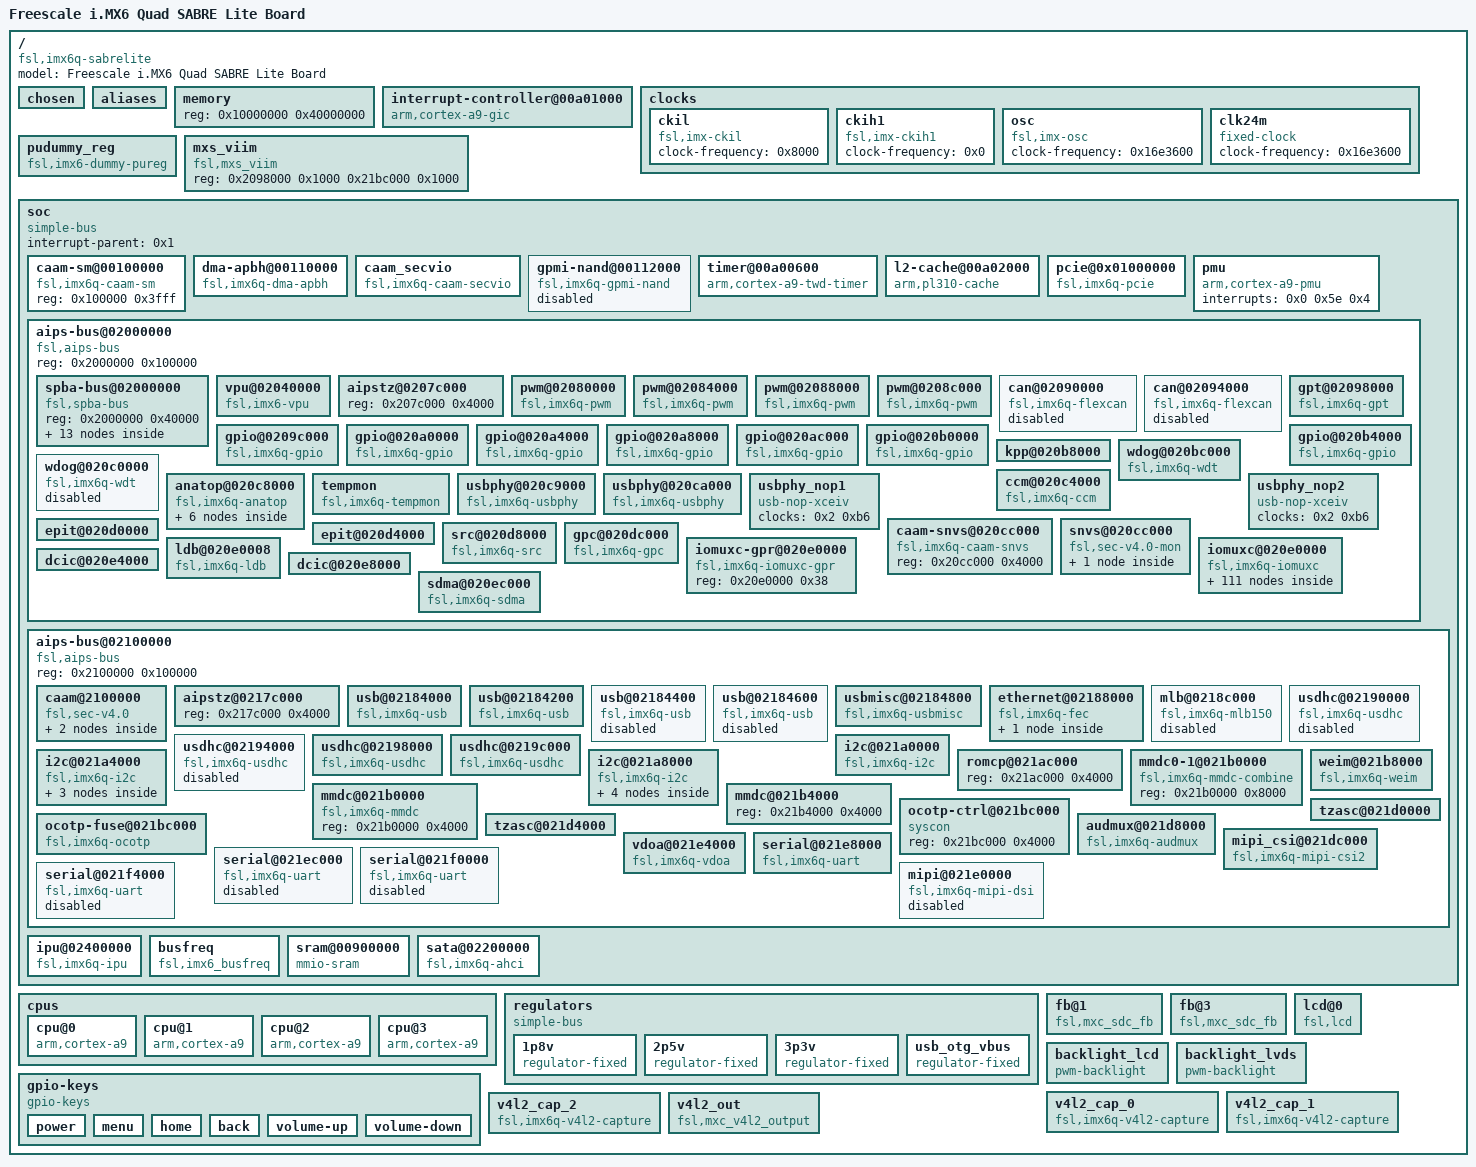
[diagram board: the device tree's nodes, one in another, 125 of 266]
/dts-v1/;

/ {
	#address-cells = <0x1>;
	#size-cells = <0x1>;
	model = "Freescale i.MX6 Quad SABRE Lite Board";
	compatible = "fsl,imx6q-sabrelite", "fsl,imx6q";

	chosen {
	//	bootargs = "console=ttymxc1,115200 root=/dev/mmcblk1p2 rw rootwait earlyprintk initcall_debug=1 loglevel=8 mem=862M no_console_suspend video=mxcfb0:dev=ldb,LDB-XGA,if=RGB888";
	bootargs = "console=ttymxc1,115200 root=/dev/mmcblk0 rw rootwait earlyprintk initcall_debug=1 loglevel=8 mem=862M no_console_suspend video=mxcfb1:dev=ldb,LDB-XGA,if=RGB666 ip=dhcp";
	};

	aliases {
		flexcan0 = "/soc/aips-bus@02000000/can@02090000";
		flexcan1 = "/soc/aips-bus@02000000/can@02094000";
		gpio0 = "/soc/aips-bus@02000000/gpio@0209c000";
		gpio1 = "/soc/aips-bus@02000000/gpio@020a0000";
		gpio2 = "/soc/aips-bus@02000000/gpio@020a4000";
		gpio3 = "/soc/aips-bus@02000000/gpio@020a8000";
		gpio4 = "/soc/aips-bus@02000000/gpio@020ac000";
		gpio5 = "/soc/aips-bus@02000000/gpio@020b0000";
		gpio6 = "/soc/aips-bus@02000000/gpio@020b4000";
		ipu0 = "/soc/ipu@02400000";
		serial0 = "/soc/aips-bus@02000000/spba-bus@02000000/serial@02020000";
		serial1 = "/soc/aips-bus@02100000/serial@021e8000";
		serial2 = "/soc/aips-bus@02100000/serial@021ec000";
		serial3 = "/soc/aips-bus@02100000/serial@021f0000";
		serial4 = "/soc/aips-bus@02100000/serial@021f4000";
		usbphy0 = "/soc/aips-bus@02000000/usbphy@020c9000";
		usbphy1 = "/soc/aips-bus@02000000/usbphy@020ca000";
		mxcfb0 = "/fb@0";
		mxcfb1 = "/fb@1";
		mxcfb2 = "/fb@2";
		mxcfb3 = "/fb@3";
	};

	memory {
		device_type = "memory";
		reg = <0x10000000 0x40000000>;
	};

	interrupt-controller@00a01000 {
		compatible = "arm,cortex-a9-gic";
		#interrupt-cells = <0x3>;
		#address-cells = <0x1>;
		#size-cells = <0x1>;
		interrupt-controller;
		reg = <0xa01000 0x1000 0xa00100 0x100>;
		linux,phandle = <0x1>;
		phandle = <0x1>;
	};

	clocks {
		#address-cells = <0x1>;
		#size-cells = <0x0>;

		ckil {
			compatible = "fsl,imx-ckil", "fixed-clock";
			clock-frequency = <0x8000>;
		};

		ckih1 {
			compatible = "fsl,imx-ckih1", "fixed-clock";
			clock-frequency = <0x0>;
		};

		osc {
			compatible = "fsl,imx-osc", "fixed-clock";
			clock-frequency = <0x16e3600>;
		};

		clk24m {
			compatible = "fixed-clock";
			#clock-cells = <0x0>;
			clock-frequency = <0x16e3600>;
			linux,phandle = <0x2a>;
			phandle = <0x2a>;
		};
		
	};

	pudummy_reg {
		compatible = "fsl,imx6-dummy-pureg";
	};

	mxs_viim {
		compatible = "fsl,mxs_viim";
		reg = <0x2098000 0x1000 0x21bc000 0x1000>;
	};

	soc {
		#address-cells = <0x1>;
		#size-cells = <0x1>;
		compatible = "simple-bus";
		interrupt-parent = <0x1>;
		ranges;

		caam-sm@00100000 {
			compatible = "fsl,imx6q-caam-sm";
			reg = <0x100000 0x3fff>;
		};

		dma-apbh@00110000 {
			compatible = "fsl,imx6q-dma-apbh", "fsl,imx28-dma-apbh";
			reg = <0x110000 0x2000>;
			interrupts = <0x0 0xd 0x4 0x0 0xd 0x4 0x0 0xd 0x4 0x0 0xd 0x4>;
			interrupt-names = "gpmi0", "gpmi1", "gpmi2", "gpmi3";
			#dma-cells = <0x1>;
			dma-channels = <0x4>;
			clocks = <0x2 0x6a>;
			linux,phandle = <0x3>;
			phandle = <0x3>;
		};

		caam_secvio {
			compatible = "fsl,imx6q-caam-secvio";
			interrupts = <0x0 0x14 0x4>;
			secvio_src = <0x8000001d>;
		};

		gpmi-nand@00112000 {
			compatible = "fsl,imx6q-gpmi-nand";
			#address-cells = <0x1>;
			#size-cells = <0x1>;
			reg = <0x112000 0x2000 0x114000 0x2000>;
			reg-names = "gpmi-nand", "bch";
			interrupts = <0x0 0xf 0x4>;
			interrupt-names = "bch";
			clocks = <0x2 0x98 0x2 0x99 0x2 0x97 0x2 0x96 0x2 0x95>;
			clock-names = "gpmi_io", "gpmi_apb", "gpmi_bch", "gpmi_bch_apb", "per1_bch";
			dmas = <0x3 0x0>;
			dma-names = "rx-tx";
			status = "disabled";
		};

		timer@00a00600 {
			compatible = "arm,cortex-a9-twd-timer";
			reg = <0xa00600 0x20>;
			interrupts = <0x1 0xd 0xf01>;
			clocks = <0x2 0xf>;
		};

		l2-cache@00a02000 {
			compatible = "arm,pl310-cache";
			reg = <0xa02000 0x1000>;
			interrupts = <0x0 0x5c 0x4>;
			cache-unified;
			cache-level = <0x2>;
			arm,tag-latency = <0x4 0x2 0x3>;
			arm,data-latency = <0x4 0x2 0x3>;
			linux,phandle = <0x2e>;
			phandle = <0x2e>;
		};

		pcie@0x01000000 {
			compatible = "fsl,imx6q-pcie", "snps,dw-pcie";
			reg = <0x1ffc000 0x4000>;
			#address-cells = <0x3>;
			#size-cells = <0x2>;
			device_type = "pci";
			ranges = <0x800 0x0 0x1f00000 0x1f00000 0x0 0x80000 0x81000000 0x0 0x0 0x1f80000 0x0 0x10000 0x82000000 0x0 0x1000000 0x1000000 0x0 0xf00000>;
			num-lanes = <0x1>;
			interrupts = <0x0 0x7b 0x4>;
			clocks = <0x2 0xbd 0x2 0xbb 0x2 0x90 0x2 0xd4>;
			clock-names = "pcie_ref_125m", "sata_ref_100m", "pcie_axi", "lvds_gate";
			status = "okay";
		};

		pmu {
			compatible = "arm,cortex-a9-pmu";
			interrupts = <0x0 0x5e 0x4>;
		};

		aips-bus@02000000 {
			compatible = "fsl,aips-bus", "simple-bus";
			#address-cells = <0x1>;
			#size-cells = <0x1>;
			reg = <0x2000000 0x100000>;
			ranges;

			spba-bus@02000000 {
				compatible = "fsl,spba-bus", "simple-bus";
				#address-cells = <0x1>;
				#size-cells = <0x1>;
				reg = <0x2000000 0x40000>;
				ranges;

				spdif@02004000 {
					compatible = "fsl,imx6q-spdif", "fsl,imx35-spdif";
					reg = <0x2004000 0x4000>;
					interrupts = <0x0 0x34 0x4>;
					dmas = <0x4 0xe 0x12 0x0 0x4 0xf 0x12 0x0>;
					dma-names = "rx", "tx";
					clocks = <0x2 0xc5 0x2 0x3 0x2 0xc5 0x2 0x6b 0x2 0x0 0x2 0x76 0x2 0x3e 0x2 0x8b 0x2 0x0 0x2 0x9c>;
					clock-names = "core", "rxtx0", "rxtx1", "rxtx2", "rxtx3", "rxtx4", "rxtx5", "rxtx6", "rxtx7", "dma";
					status = "disabled";
				};

/*
				ecspi@02008000 {
					#address-cells = <0x1>;
					#size-cells = <0x0>;
					compatible = "fsl,imx6q-ecspi", "fsl,imx51-ecspi";
					reg = <0x2008000 0x4000>;
					interrupts = <0x0 0x1f 0x4>;
					clocks = <0x2 0x70 0x2 0x70>;
					clock-names = "ipg", "per";
					status = "okay";
					fsl,spi-num-chipselects = <0x1>;
					cs-gpios = <0x5 0x13 0x0>;
					pinctrl-names = "default";
					pinctrl-0 = <0x6>;

					m25p80@0 {
						compatible = "sst,sst25vf016b";
						spi-max-frequency = <0x1312d00>;
						reg = <0x0>;
						#address-cells = <0x1>;
						#size-cells = <0x1>;

						partition@0 {
							label = "U-Boot";
							reg = <0x0 0xc0000>;
							read-only;
						};

						partition@C0000 {
							label = "env";
							reg = <0xc0000 0x2000>;
							read-only;
						};

						partition@C2000 {
							label = "Kernel";
							reg = <0xc2000 0x13e000>;
						};
					};
				};
*/
				ecspi@0200c000 {
					#address-cells = <0x1>;
					#size-cells = <0x0>;
					compatible = "fsl,imx6q-ecspi", "fsl,imx51-ecspi";
					reg = <0x200c000 0x4000>;
					interrupts = <0x0 0x20 0x4>;
					clocks = <0x2 0x71 0x2 0x71>;
					clock-names = "ipg", "per";
					status = "disabled";
				};

				ecspi@02010000 {
					#address-cells = <0x1>;
					#size-cells = <0x0>;
					compatible = "fsl,imx6q-ecspi", "fsl,imx51-ecspi";
					reg = <0x2010000 0x4000>;
					interrupts = <0x0 0x21 0x4>;
					clocks = <0x2 0x72 0x2 0x72>;
					clock-names = "ipg", "per";
					status = "disabled";
				};

				ecspi@02014000 {
					#address-cells = <0x1>;
					#size-cells = <0x0>;
					compatible = "fsl,imx6q-ecspi", "fsl,imx51-ecspi";
					reg = <0x2014000 0x4000>;
					interrupts = <0x0 0x22 0x4>;
					clocks = <0x2 0x73 0x2 0x73>;
					clock-names = "ipg", "per";
					status = "disabled";
				};

				serial@02020000 {
					compatible = "fsl,imx6q-uart", "fsl,imx21-uart";
					reg = <0x2020000 0x4000>;
					interrupts = <0x0 0x1a 0x4>;
					clocks = <0x2 0xa0 0x2 0xa1>;
					clock-names = "ipg", "per";
					dmas = <0x4 0x19 0x4 0x0 0x4 0x1a 0x4 0x0>;
					dma-names = "rx", "tx";
					status = "okay";
					pinctrl-names = "default";
					pinctrl-0 = <0x7>;
				};

				esai@02024000 {
					compatible = "fsl,imx6q-esai";
					reg = <0x2024000 0x4000>;
					interrupts = <0x0 0x33 0x4>;
					clocks = <0x2 0x76 0x2 0x9c>;
					clock-names = "core", "dma";
					fsl,esai-dma-events = <0x18 0x17>;
					fsl,flags = <0x1>;
					status = "disabled";
				};

				ssi@02028000 {
					compatible = "fsl,imx6q-ssi", "fsl,imx21-ssi";
					reg = <0x2028000 0x4000>;
					interrupts = <0x0 0x2e 0x4>;
					clocks = <0x2 0xb2 0x2 0x9d>;
					clock-names = "ipg", "baud";
					dmas = <0x4 0x25 0x1 0x0 0x4 0x26 0x1 0x0>;
					dma-names = "rx", "tx";
					status = "okay";
					fsl,mode = "i2s-slave";
					linux,phandle = <0x31>;
					phandle = <0x31>;
				};

				ssi@0202c000 {
					compatible = "fsl,imx6q-ssi", "fsl,imx21-ssi";
					reg = <0x202c000 0x4000>;
					interrupts = <0x0 0x2f 0x4>;
					clocks = <0x2 0xb3 0x2 0x9e>;
					clock-names = "ipg", "baud";
					dmas = <0x4 0x29 0x1 0x0 0x4 0x2a 0x1 0x0>;
					dma-names = "rx", "tx";
					status = "disabled";
				};

				ssi@02030000 {
					compatible = "fsl,imx6q-ssi", "fsl,imx21-ssi";
					reg = <0x2030000 0x4000>;
					interrupts = <0x0 0x30 0x4>;
					clocks = <0x2 0xb4 0x2 0x9f>;
					clock-names = "ipg", "baud";
					dmas = <0x4 0x2d 0x1 0x0 0x4 0x2e 0x1 0x0>;
					dma-names = "rx", "tx";
					status = "disabled";
				};

				asrc@02034000 {
					compatible = "fsl,imx53-asrc";
					reg = <0x2034000 0x4000>;
					interrupts = <0x0 0x32 0x4>;
					clocks = <0x2 0x6b 0x2 0x9c>;
					clock-names = "core", "dma";
					dmas = <0x4 0x11 0x14 0x1 0x4 0x12 0x14 0x1 0x4 0x13 0x14 0x1 0x4 0x14 0x14 0x1 0x4 0x15 0x14 0x1 0x4 0x16 0x14 0x1>;
					dma-names = "rxa", "rxb", "rxc", "txa", "txb", "txc";
					status = "okay";
				};

				asrc_p2p {
					compatible = "fsl,imx6q-asrc-p2p";
					fsl,output-rate = <0xbb80>;
					fsl,output-width = <0x10>;
					fsl,asrc-dma-rx-events = <0x11 0x12 0x13>;
					fsl,asrc-dma-tx-events = <0x14 0x15 0x16>;
					status = "okay";
				};

				spba@0203c000 {
					reg = <0x203c000 0x4000>;
				};

				ecspi@02018000 {
					#address-cells = <0x1>;
					#size-cells = <0x0>;
					compatible = "fsl,imx6q-ecspi", "fsl,imx51-ecspi";
					reg = <0x2018000 0x4000>;
					interrupts = <0x0 0x23 0x4>;
					clocks = <0x2 0x74 0x2 0x74>;
					clock-names = "ipg", "per";
					status = "disabled";
				};
			};

			vpu@02040000 {
				compatible = "fsl,imx6-vpu";
				reg = <0x2040000 0x3c000>;
				reg-names = "vpu_regs";
				interrupts = <0x0 0x3 0x1 0x0 0xc 0x4>;
				interrupt-names = "vpu_jpu_irq", "vpu_ipi_irq";
				clocks = <0x2 0xa8 0x2 0x8c 0x2 0x8e>;
				clock-names = "vpu_clk", "mmdc_ch0_axi", "ocram";
				iramsize = <0x21000>;
				iram = <0x8>;
				resets = <0x9 0x1>;
				pu-supply = <0xa>;
				status = "okay";
			};

			aipstz@0207c000 {
				reg = <0x207c000 0x4000>;
			};

			pwm@02080000 {
				#pwm-cells = <0x2>;
				compatible = "fsl,imx6q-pwm", "fsl,imx27-pwm";
				reg = <0x2080000 0x4000>;
				interrupts = <0x0 0x53 0x4>;
				clocks = <0x2 0x3e 0x2 0x91>;
				clock-names = "ipg", "per";
				pinctrl-names = "default";
				pinctrl-0 = <0xb>;
				status = "okay";
				linux,phandle = <0x34>;
				phandle = <0x34>;
			};

			pwm@02084000 {
				#pwm-cells = <0x2>;
				compatible = "fsl,imx6q-pwm", "fsl,imx27-pwm";
				reg = <0x2084000 0x4000>;
				interrupts = <0x0 0x54 0x4>;
				clocks = <0x2 0x3e 0x2 0x92>;
				clock-names = "ipg", "per";
			};

			pwm@02088000 {
				#pwm-cells = <0x2>;
				compatible = "fsl,imx6q-pwm", "fsl,imx27-pwm";
				reg = <0x2088000 0x4000>;
				interrupts = <0x0 0x55 0x4>;
				clocks = <0x2 0x3e 0x2 0x93>;
				clock-names = "ipg", "per";
				pinctrl-names = "default";
				pinctrl-0 = <0xc>;
				status = "okay";
				linux,phandle = <0x26>;
				phandle = <0x26>;
			};

			pwm@0208c000 {
				#pwm-cells = <0x2>;
				compatible = "fsl,imx6q-pwm", "fsl,imx27-pwm";
				reg = <0x208c000 0x4000>;
				interrupts = <0x0 0x56 0x4>;
				clocks = <0x2 0x3e 0x2 0x94>;
				clock-names = "ipg", "per";
				pinctrl-names = "default";
				pinctrl-0 = <0xd>;
				status = "okay";
				linux,phandle = <0x35>;
				phandle = <0x35>;
			};

			can@02090000 {
				compatible = "fsl,imx6q-flexcan";
				reg = <0x2090000 0x4000>;
				interrupts = <0x0 0x6e 0x4>;
				clocks = <0x2 0x6c 0x2 0x6d>;
				clock-names = "ipg", "per";
				gpr = <0xe>;
				status = "disabled";
			};

			can@02094000 {
				compatible = "fsl,imx6q-flexcan";
				reg = <0x2094000 0x4000>;
				interrupts = <0x0 0x6f 0x4>;
				clocks = <0x2 0x6e 0x2 0x6f>;
				clock-names = "ipg", "per";
				gpr = <0xe>;
				status = "disabled";
			};

			gpt@02098000 {
				compatible = "fsl,imx6q-gpt";
				reg = <0x2098000 0x4000>;
				interrupts = <0x0 0x37 0x4>;
				clocks = <0x2 0x77 0x2 0x78>;
				clock-names = "ipg", "per";
				status = "okay";
			};

			gpio@0209c000 {
				compatible = "fsl,imx6q-gpio", "fsl,imx35-gpio";
				reg = <0x209c000 0x4000>;
				interrupts = <0x0 0x42 0x4 0x0 0x43 0x4>;
				gpio-controller;
				#gpio-cells = <0x2>;
				interrupt-controller;
				#interrupt-cells = <0x2>;
				linux,phandle = <0x1a>;
				phandle = <0x1a>;
			};

			gpio@020a0000 {
				compatible = "fsl,imx6q-gpio", "fsl,imx35-gpio";
				reg = <0x20a0000 0x4000>;
				interrupts = <0x0 0x44 0x4 0x0 0x45 0x4>;
				gpio-controller;
				#gpio-cells = <0x2>;
				interrupt-controller;
				#interrupt-cells = <0x2>;
				linux,phandle = <0x1f>;
				phandle = <0x1f>;
			};

			gpio@020a4000 {
				compatible = "fsl,imx6q-gpio", "fsl,imx35-gpio";
				reg = <0x20a4000 0x4000>;
				interrupts = <0x0 0x46 0x4 0x0 0x47 0x4>;
				gpio-controller;
				#gpio-cells = <0x2>;
				interrupt-controller;
				#interrupt-cells = <0x2>;
				linux,phandle = <0x5>;
				phandle = <0x5>;
			};

			gpio@020a8000 {
				compatible = "fsl,imx6q-gpio", "fsl,imx35-gpio";
				reg = <0x20a8000 0x4000>;
				interrupts = <0x0 0x48 0x4 0x0 0x49 0x4>;
				gpio-controller;
				#gpio-cells = <0x2>;
				interrupt-controller;
				#interrupt-cells = <0x2>;
				linux,phandle = <0x2b>;
				phandle = <0x2b>;
			};

			gpio@020ac000 {
				compatible = "fsl,imx6q-gpio", "fsl,imx35-gpio";
				reg = <0x20ac000 0x4000>;
				interrupts = <0x0 0x4a 0x4 0x0 0x4b 0x4>;
				gpio-controller;
				#gpio-cells = <0x2>;
				interrupt-controller;
				#interrupt-cells = <0x2>;
			};

			gpio@020b0000 {
				compatible = "fsl,imx6q-gpio", "fsl,imx35-gpio";
				reg = <0x20b0000 0x4000>;
				interrupts = <0x0 0x4c 0x4 0x0 0x4d 0x4>;
				gpio-controller;
				#gpio-cells = <0x2>;
				interrupt-controller;
				#interrupt-cells = <0x2>;
				linux,phandle = <0x25>;
				phandle = <0x25>;
			};

			gpio@020b4000 {
				compatible = "fsl,imx6q-gpio", "fsl,imx35-gpio";
				reg = <0x20b4000 0x4000>;
				interrupts = <0x0 0x4e 0x4 0x0 0x4f 0x4>;
				gpio-controller;
				#gpio-cells = <0x2>;
				interrupt-controller;
				#interrupt-cells = <0x2>;
				linux,phandle = <0x1c>;
				phandle = <0x1c>;
			};

			kpp@020b8000 {
				reg = <0x20b8000 0x4000>;
				interrupts = <0x0 0x52 0x4>;
			};

			wdog@020bc000 {
				compatible = "fsl,imx6q-wdt", "fsl,imx21-wdt";
				reg = <0x20bc000 0x4000>;
				interrupts = <0x0 0x50 0x4>;
				clocks = <0x2 0x0>;
			};

			wdog@020c0000 {
				compatible = "fsl,imx6q-wdt", "fsl,imx21-wdt";
				reg = <0x20c0000 0x4000>;
				interrupts = <0x0 0x51 0x4>;
				clocks = <0x2 0x0>;
				status = "disabled";
			};

			ccm@020c4000 {
				compatible = "fsl,imx6q-ccm";
				reg = <0x20c4000 0x4000>;
				interrupts = <0x0 0x57 0x4 0x0 0x58 0x4>;
				#clock-cells = <0x1>;
				linux,phandle = <0x2>;
				phandle = <0x2>;
			};

			anatop@020c8000 {
				compatible = "fsl,imx6q-anatop", "syscon", "simple-bus";
				reg = <0x20c8000 0x1000>;
				interrupts = <0x0 0x31 0x4 0x0 0x36 0x4 0x0 0x7f 0x4>;
				linux,phandle = <0xf>;
				phandle = <0xf>;

				regulator-1p1@110 {
					compatible = "fsl,anatop-regulator";
					regulator-name = "vdd1p1";
					regulator-min-microvolt = <0xc3500>;
					regulator-max-microvolt = <0x14fb18>;
					regulator-always-on;
					anatop-reg-offset = <0x110>;
					anatop-vol-bit-shift = <0x8>;
					anatop-vol-bit-width = <0x5>;
					anatop-min-bit-val = <0x4>;
					anatop-min-voltage = <0xc3500>;
					anatop-max-voltage = <0x14fb18>;
				};

				regulator-3p0@120 {
					compatible = "fsl,anatop-regulator";
					regulator-name = "vdd3p0";
					regulator-min-microvolt = <0x2ab980>;
					regulator-max-microvolt = <0x3010b0>;
					regulator-always-on;
					anatop-reg-offset = <0x120>;
					anatop-vol-bit-shift = <0x8>;
					anatop-vol-bit-width = <0x5>;
					anatop-min-bit-val = <0x0>;
					anatop-min-voltage = <0x280de8>;
					anatop-max-voltage = <0x33e140>;
				};

				regulator-2p5@130 {
					compatible = "fsl,anatop-regulator";
					regulator-name = "vdd2p5";
					regulator-min-microvolt = <0x1e8480>;
					regulator-max-microvolt = <0x29f630>;
					regulator-always-on;
					anatop-reg-offset = <0x130>;
					anatop-vol-bit-shift = <0x8>;
					anatop-vol-bit-width = <0x5>;
					anatop-min-bit-val = <0x0>;
					anatop-min-voltage = <0x1e8480>;
					anatop-max-voltage = <0x29f630>;
				};

				regulator-vddcore@140 {
					compatible = "fsl,anatop-regulator";
					regulator-name = "cpu";
					regulator-min-microvolt = <0xb1008>;
					regulator-max-microvolt = <0x162010>;
					regulator-always-on;
					anatop-reg-offset = <0x140>;
					anatop-vol-bit-shift = <0x0>;
					anatop-vol-bit-width = <0x5>;
					anatop-delay-reg-offset = <0x170>;
					anatop-delay-bit-shift = <0x18>;
					anatop-delay-bit-width = <0x2>;
					anatop-min-bit-val = <0x1>;
					anatop-min-voltage = <0xb1008>;
					anatop-max-voltage = <0x162010>;
					linux,phandle = <0x2f>;
					phandle = <0x2f>;
				};

				regulator-vddpu@140 {
					compatible = "fsl,anatop-regulator";
					regulator-name = "vddpu";
					regulator-min-microvolt = <0xb1008>;
					regulator-max-microvolt = <0x162010>;
					anatop-reg-offset = <0x140>;
					anatop-vol-bit-shift = <0x9>;
					anatop-vol-bit-width = <0x5>;
					anatop-delay-reg-offset = <0x170>;
					anatop-delay-bit-shift = <0x1a>;
					anatop-delay-bit-width = <0x2>;
					anatop-min-bit-val = <0x1>;
					anatop-min-voltage = <0xb1008>;
					anatop-max-voltage = <0x162010>;
					linux,phandle = <0xa>;
					phandle = <0xa>;
				};

				regulator-vddsoc@140 {
					compatible = "fsl,anatop-regulator";
					regulator-name = "vddsoc";
					regulator-min-microvolt = <0xb1008>;
					regulator-max-microvolt = <0x162010>;
					regulator-always-on;
					anatop-reg-offset = <0x140>;
					anatop-vol-bit-shift = <0x12>;
					anatop-vol-bit-width = <0x5>;
					anatop-delay-reg-offset = <0x170>;
					anatop-delay-bit-shift = <0x1c>;
					anatop-delay-bit-width = <0x2>;
					anatop-min-bit-val = <0x1>;
					anatop-min-voltage = <0xb1008>;
					anatop-max-voltage = <0x162010>;
					linux,phandle = <0x30>;
					phandle = <0x30>;
				};
			};

			tempmon {
				compatible = "fsl,imx6q-tempmon";
				interrupts = <0x0 0x31 0x4>;
				fsl,tempmon = <0xf>;
				fsl,tempmon-data = <0x10>;
				clocks = <0x2 0xac>;
			};

			usbphy@020c9000 {
				compatible = "fsl,imx6q-usbphy", "fsl,imx23-usbphy";
				reg = <0x20c9000 0x1000>;
				interrupts = <0x0 0x2c 0x4>;
				clocks = <0x2 0xb6>;
				fsl,anatop = <0xf>;
				linux,phandle = <0x12>;
				phandle = <0x12>;
			};

			usbphy@020ca000 {
				compatible = "fsl,imx6q-usbphy", "fsl,imx23-usbphy";
				reg = <0x20ca000 0x1000>;
				interrupts = <0x0 0x2d 0x4>;
				clocks = <0x2 0xb7>;
				fsl,anatop = <0xf>;
				linux,phandle = <0x16>;
				phandle = <0x16>;
			};

			usbphy_nop1 {
				compatible = "usb-nop-xceiv";
				clocks = <0x2 0xb6>;
				clock-names = "main_clk";
				linux,phandle = <0x17>;
				phandle = <0x17>;
			};

			usbphy_nop2 {
				compatible = "usb-nop-xceiv";
				clocks = <0x2 0xb6>;
				clock-names = "main_clk";
				linux,phandle = <0x18>;
				phandle = <0x18>;
			};

			caam-snvs@020cc000 {
				compatible = "fsl,imx6q-caam-snvs";
				reg = <0x20cc000 0x4000>;
			};

			snvs@020cc000 {
				compatible = "fsl,sec-v4.0-mon", "simple-bus";
				#address-cells = <0x1>;
				#size-cells = <0x1>;
				ranges = <0x0 0x20cc000 0x4000>;

				snvs-rtc-lp@34 {
					compatible = "fsl,sec-v4.0-mon-rtc-lp";
					reg = <0x34 0x58>;
					interrupts = <0x0 0x13 0x4 0x0 0x14 0x4>;
				};
			};

			epit@020d0000 {
				reg = <0x20d0000 0x4000>;
				interrupts = <0x0 0x38 0x4>;
			};

			epit@020d4000 {
				reg = <0x20d4000 0x4000>;
				interrupts = <0x0 0x39 0x4>;
			};

			src@020d8000 {
				compatible = "fsl,imx6q-src", "fsl,imx51-src";
				reg = <0x20d8000 0x4000>;
				interrupts = <0x0 0x5b 0x4 0x0 0x60 0x4>;
				#reset-cells = <0x1>;
				linux,phandle = <0x9>;
				phandle = <0x9>;
			};

			gpc@020dc000 {
				compatible = "fsl,imx6q-gpc";
				reg = <0x20dc000 0x4000>;
				interrupts = <0x0 0x59 0x4 0x0 0x5a 0x4>;
				clocks = <0x2 0x7a 0x2 0x4a 0x2 0x79 0x2 0x1a 0x2 0x8f 0x2 0xa8 0x2 0x3e>;
				clock-names = "gpu3d_core", "gpu3d_shader", "gpu2d_core", "gpu2d_axi", "openvg_axi", "vpu_axi", "ipg";
				pu-supply = <0xa>;
			};

			iomuxc-gpr@020e0000 {
				compatible = "fsl,imx6q-iomuxc-gpr", "syscon";
				reg = <0x20e0000 0x38>;
				linux,phandle = <0xe>;
				phandle = <0xe>;
			};

			iomuxc@020e0000 {
				reg = <0x20e0000 0x4000>;
				compatible = "fsl,imx6q-iomuxc";
				pinctrl-names = "default";
				pinctrl-0 = <0x11>;

				audmux {

					audmux-1 {
						fsl,pins = <0x54 0x368 0x7b4 0x3 0x0 0x130b0 0x35c 0x744 0x7c4 0x3 0x1 0x130b0 0x50 0x364 0x7b8 0x3 0x0 0x110b0 0x4c 0x360 0x7c8 0x3 0x0 0x130b0>;
						linux,phandle = <0x2c>;
						phandle = <0x2c>;
					};

					audmux-2 {
						fsl,pins = <0x274 0x644 0x0 0x4 0x0 0x130b0 0x268 0x638 0x0 0x4 0x0 0x130b0 0x26c 0x63c 0x0 0x4 0x0 0x110b0 0x270 0x640 0x0 0x4 0x0 0x130b0>;
					};

					audmux-3 {
						fsl,pins = <0x1b0 0x4c4 0x7dc 0x3 0x0 0x130b0 0x1b8 0x4cc 0x7e0 0x3 0x0 0x130b0 0x1bc 0x4d0 0x7cc 0x3 0x0 0x130b0>;
					};
				};

				ecspi1 {

					ecspi1_cs_grp-1 {
						fsl,pins = <0x9c 0x3b0 0x0 0x5 0x0 0x80000000>;
					};

					ecspi1grp-1 {
						fsl,pins = <0x94 0x3a8 0x7f8 0x1 0x0 0x100b1 0x98 0x3ac 0x7fc 0x1 0x0 0x100b1 0x90 0x3a4 0x7f4 0x1 0x0 0x100b1>;
						linux,phandle = <0x6>;
						phandle = <0x6>;
					};

					ecspi1grp-2 {
						fsl,pins = <0x200 0x5d0 0x7f8 0x0 0x2 0x100b1 0x1fc 0x5cc 0x7fc 0x0 0x2 0x100b1 0x1f8 0x5c8 0x7f4 0x0 0x2 0x100b1>;
					};
				};

				ecspi3 {

					ecspi3grp-1 {
						fsl,pins = <0x178 0x48c 0x0 0x2 0x0 0x100b1 0x174 0x488 0x0 0x2 0x0 0x100b1 0x170 0x484 0x0 0x2 0x0 0x100b1>;
					};
				};

				enet {

					enetgrp-1 {
						fsl,pins = <0x1d0 0x4e4 0x840 0x1 0x0 0x1b0b0 0x1f4 0x508 0x0 0x1 0x0 0x1b0b0 0x58 0x36c 0x0 0x1 0x0 0x1b0b0 0x5c 0x370 0x0 0x1 0x0 0x1b0b0 0x60 0x374 0x0 0x1 0x0 0x1b0b0 0x64 0x378 0x0 0x1 0x0 0x1b0b0 0x68 0x37c 0x0 0x1 0x0 0x1b0b0 0x74 0x388 0x0 0x1 0x0 0x1b0b0 0x1d4 0x4e8 0x0 0x1 0x0 0x1b0b0 0x84 0x398 0x844 0x1 0x0 0x1b0b0 0x70 0x384 0x848 0x1 0x0 0x1b0b0 0x78 0x38c 0x84c 0x1 0x0 0x1b0b0 0x7c 0x390 0x850 0x1 0x0 0x1b0b0 0x80 0x394 0x854 0x1 0x0 0x1b0b0 0x6c 0x380 0x858 0x1 0x0 0x1b0b0 0x248 0x618 0x83c 0x2 0x1 0x4001b0a8>;
					};

					enetgrp-2 {
						fsl,pins = <0x200 0x5d0 0x840 0x1 0x1 0x1b0b0 0x208 0x5d8 0x0 0x4 0x0 0x1b0b0 0x58 0x36c 0x0 0x1 0x0 0x1b0b0 0x5c 0x370 0x0 0x1 0x0 0x1b0b0 0x60 0x374 0x0 0x1 0x0 0x1b0b0 0x64 0x378 0x0 0x1 0x0 0x1b0b0 0x68 0x37c 0x0 0x1 0x0 0x1b0b0 0x74 0x388 0x0 0x1 0x0 0x1b0b0 0x1d4 0x4e8 0x0 0x1 0x0 0x1b0b0 0x84 0x398 0x844 0x1 0x0 0x1b0b0 0x70 0x384 0x848 0x1 0x0 0x1b0b0 0x78 0x38c 0x84c 0x1 0x0 0x1b0b0 0x7c 0x390 0x850 0x1 0x0 0x1b0b0 0x80 0x394 0x854 0x1 0x0 0x1b0b0 0x6c 0x380 0x858 0x1 0x0 0x1b0b0 0x248 0x618 0x83c 0x2 0x1 0x4001b0a8>;
					};

					enetgrp-3 {
						fsl,pins = <0x1d0 0x4e4 0x840 0x1 0x0 0x1b0b0 0x1f4 0x508 0x0 0x1 0x0 0x1b0b0 0x58 0x36c 0x0 0x1 0x0 0x1b0b0 0x5c 0x370 0x0 0x1 0x0 0x1b0b0 0x60 0x374 0x0 0x1 0x0 0x1b0b0 0x64 0x378 0x0 0x1 0x0 0x1b0b0 0x68 0x37c 0x0 0x1 0x0 0x1b0b0 0x74 0x388 0x0 0x1 0x0 0x1b0b0 0x1d4 0x4e8 0x0 0x1 0x0 0x1b0b0 0x84 0x398 0x844 0x1 0x0 0x1b0b0 0x70 0x384 0x848 0x1 0x0 0x1b0b0 0x78 0x38c 0x84c 0x1 0x0 0x1b0b0 0x7c 0x390 0x850 0x1 0x0 0x1b0b0 0x80 0x394 0x854 0x1 0x0 0x1b0b0 0x6c 0x380 0x858 0x1 0x0 0x1b0b0 0x1e8 0x4fc 0x0 0x1 0x0 0x1b0b0>;
					};

					enetgrp-4 {
						fsl,pins = <0x1d0 0x4e4 0x840 0x1 0x0 0x1b0b0 0x1f4 0x508 0x0 0x1 0x0 0x1b0b0 0x58 0x36c 0x0 0x1 0x0 0x1b0b0 0x5c 0x370 0x0 0x1 0x0 0x1b0b0 0x60 0x374 0x0 0x1 0x0 0x1b0b0 0x64 0x378 0x0 0x1 0x0 0x1b0b0 0x68 0x37c 0x0 0x1 0x0 0x1b0b0 0x74 0x388 0x0 0x1 0x0 0x1b0b0 0x1d4 0x4e8 0x0 0x1 0x0 0x1b0b0 0x84 0x398 0x844 0x1 0x0 0x1b0b0 0x70 0x384 0x848 0x1 0x0 0x1b0b0 0x78 0x38c 0x84c 0x1 0x0 0x1b0b0 0x7c 0x390 0x850 0x1 0x0 0x1b0b0 0x80 0x394 0x854 0x1 0x0 0x1b0b0 0x6c 0x380 0x858 0x1 0x0 0x1b0b0>;
						linux,phandle = <0x19>;
						phandle = <0x19>;
					};
				};

				esai {

					esaigrp-1 {
						fsl,pins = <0x1e4 0x4f8 0x868 0x2 0x0 0x1b030 0x1dc 0x4f0 0x870 0x2 0x0 0x1b030 0x1e0 0x4f4 0x860 0x2 0x0 0x1b030 0x1e8 0x4fc 0x880 0x2 0x0 0x1b030 0x1ec 0x500 0x87c 0x2 0x0 0x1b030 0x1f0 0x504 0x884 0x2 0x0 0x1b030 0x1f4 0x508 0x888 0x2 0x0 0x1b030 0x2ec 0x6d4 0x874 0x2 0x1 0x1b030 0x2f0 0x6d8 0x878 0x2 0x1 0x1b030>;
					};

					esaigrp-2 {
						fsl,pins = <0x1dc 0x4f0 0x870 0x2 0x0 0x1b030 0x1e0 0x4f4 0x860 0x2 0x0 0x1b030 0x1e8 0x4fc 0x880 0x2 0x0 0x1b030 0x23c 0x60c 0x87c 0x0 0x1 0x1b030 0x1f0 0x504 0x884 0x2 0x0 0x1b030 0x1f4 0x508 0x888 0x2 0x0 0x1b030 0x24c 0x61c 0x874 0x0 0x0 0x1b030 0x2f0 0x6d8 0x878 0x2 0x1 0x1b030 0x1d0 0x4e4 0x86c 0x2 0x0 0x1b030 0x228 0x5f8 0x85c 0x0 0x1 0x1b030>;
					};
				};

				flexcan1 {

					flexcan1grp-1 {
						fsl,pins = <0x20c 0x5dc 0x7e4 0x2 0x0 0x80000000 0x208 0x5d8 0x0 0x2 0x0 0x80000000>;
					};

					flexcan1grp-2 {
						fsl,pins = <0x240 0x610 0x0 0x3 0x0 0x80000000 0x20c 0x5dc 0x7e4 0x2 0x0 0x80000000>;
					};
				};

				flexcan2 {

					flexcan2grp-1 {
						fsl,pins = <0x218 0x5e8 0x0 0x0 0x0 0x80000000 0x21c 0x5ec 0x7e8 0x0 0x0 0x80000000>;
					};
				};

				gpmi-nand {

					gpmi-nand-1 {
						fsl,pins = <0x2d4 0x6bc 0x0 0x0 0x0 0xb0b1 0x2d8 0x6c0 0x0 0x0 0x0 0xb0b1 0x2dc 0x6c4 0x0 0x0 0x0 0xb0b1 0x2e0 0x6c8 0x0 0x0 0x0 0xb000 0x2e4 0x6cc 0x0 0x0 0x0 0xb0b1 0x2e8 0x6d0 0x0 0x0 0x0 0xb0b1 0x2f4 0x6dc 0x0 0x1 0x0 0xb0b1 0x2f8 0x6e0 0x0 0x1 0x0 0xb0b1 0x2fc 0x6e4 0x0 0x0 0x0 0xb0b1 0x300 0x6e8 0x0 0x0 0x0 0xb0b1 0x304 0x6ec 0x0 0x0 0x0 0xb0b1 0x308 0x6f0 0x0 0x0 0x0 0xb0b1 0x30c 0x6f4 0x0 0x0 0x0 0xb0b1 0x310 0x6f8 0x0 0x0 0x0 0xb0b1 0x314 0x6fc 0x0 0x0 0x0 0xb0b1 0x318 0x700 0x0 0x0 0x0 0xb0b1 0x31c 0x704 0x0 0x2 0x0 0xb1>;
					};
				};

				hdmi_hdcp {

					hdmihdcpgrp-1 {
						fsl,pins = <0x210 0x5e0 0x890 0x2 0x1 0x4001b8b1 0x214 0x5e4 0x894 0x2 0x1 0x4001b8b1>;
					};

					hdmihdcpgrp-2 {
						fsl,pins = <0x8c 0x3a0 0x890 0x4 0x0 0x4001b8b1 0x90 0x3a4 0x894 0x4 0x0 0x4001b8b1>;
					};

					hdmihdcpgrp-3 {
						fsl,pins = <0x8c 0x3a0 0x890 0x4 0x0 0x4001b8b1 0x214 0x5e4 0x894 0x2 0x1 0x4001b8b1>;
					};
				};

				hdmi_cec {

					hdmicecgrp-1 {
						fsl,pins = <0x88 0x39c 0x88c 0x6 0x0 0x1f8b0>;
					};

					hdmicecgrp-2 {
						fsl,pins = <0x20c 0x5dc 0x88c 0x6 0x1 0x1f8b0>;
					};
				};

				i2c1 {

					i2c1grp-1 {
						fsl,pins = <0xa4 0x3b8 0x898 0x6 0x0 0x4001b8b1 0xc4 0x3d8 0x89c 0x1 0x0 0x4001b8b1>;
						linux,phandle = <0x20>;
						phandle = <0x20>;
					};

					i2c1grp-2 {
						fsl,pins = <0x278 0x648 0x89c 0x4 0x1 0x4001b8b1 0x27c 0x64c 0x898 0x4 0x1 0x4001b8b1>;
					};
				};

				i2c2 {

					i2c2grp-1 {
						fsl,pins = <0x8c 0x3a0 0x8a0 0x6 0x0 0x4001b8b1 0x90 0x3a4 0x8a4 0x6 0x0 0x4001b8b1>;
					};

					i2c2grp-2 {
						fsl,pins = <0x210 0x5e0 0x8a0 0x4 0x1 0x4001b8b1 0x214 0x5e4 0x8a4 0x4 0x1 0x4001b8b1>;
						linux,phandle = <0x22>;
						phandle = <0x22>;
					};

					i2c2grp-3 {
						fsl,pins = <0x8c 0x3a0 0x8a0 0x6 0x0 0x4001b8b1 0x214 0x5e4 0x8a4 0x4 0x1 0x4001b8b1>;
					};
				};

				i2c3 {

					i2c3grp-1 {
						fsl,pins = <0x94 0x3a8 0x8a8 0x6 0x0 0x4001b8b1 0x98 0x3ac 0x8ac 0x6 0x0 0x4001b8b1>;
					};

					i2c3grp-2 {
						fsl,pins = <0x22c 0x5fc 0x8a8 0x2 0x1 0x4001b8b1 0x230 0x600 0x8ac 0x2 0x1 0x4001b8b1>;
					};

					i2c3grp-3 {
						fsl,pins = <0x23c 0x60c 0x8a8 0x6 0x2 0x4001b8b1 0x248 0x618 0x8ac 0x6 0x2 0x4001b8b1>;
						linux,phandle = <0x27>;
						phandle = <0x27>;
					};

					i2c3grp-4 {
						fsl,pins = <0x22c 0x5fc 0x8a8 0x2 0x1 0x4001b8b1 0x98 0x3ac 0x8ac 0x6 0x0 0x4001b8b1>;
					};
				};

				ipu1 {

					ipu1grp-1 {
						fsl,pins = <0x15c 0x470 0x0 0x0 0x0 0x10 0x160 0x474 0x0 0x0 0x0 0x10 0x164 0x478 0x0 0x0 0x0 0x10 0x168 0x47c 0x0 0x0 0x0 0x10 0x16c 0x480 0x0 0x0 0x0 0x80000000 0x170 0x484 0x0 0x0 0x0 0x10 0x174 0x488 0x0 0x0 0x0 0x10 0x178 0x48c 0x0 0x0 0x0 0x10 0x17c 0x490 0x0 0x0 0x0 0x10 0x180 0x494 0x0 0x0 0x0 0x10 0x184 0x498 0x0 0x0 0x0 0x10 0x188 0x49c 0x0 0x0 0x0 0x10 0x18c 0x4a0 0x0 0x0 0x0 0x10 0x190 0x4a4 0x0 0x0 0x0 0x10 0x194 0x4a8 0x0 0x0 0x0 0x10 0x198 0x4ac 0x0 0x0 0x0 0x10 0x19c 0x4b0 0x0 0x0 0x0 0x10 0x1a0 0x4b4 0x0 0x0 0x0 0x10 0x1a4 0x4b8 0x0 0x0 0x0 0x10 0x1a8 0x4bc 0x0 0x0 0x0 0x10 0x1ac 0x4c0 0x0 0x0 0x0 0x10 0x1b0 0x4c4 0x0 0x0 0x0 0x10 0x1b4 0x4c8 0x0 0x0 0x0 0x10 0x1b8 0x4cc 0x0 0x0 0x0 0x10 0x1bc 0x4d0 0x0 0x0 0x0 0x10 0x1c0 0x4d4 0x0 0x0 0x0 0x10 0x1c4 0x4d8 0x0 0x0 0x0 0x10 0x1c8 0x4dc 0x0 0x0 0x0 0x10 0x1cc 0x4e0 0x0 0x0 0x0 0x10>;
					};

					ipu1grp-2 {
						fsl,pins = <0x288 0x658 0x0 0x0 0x0 0x80000000 0x28c 0x65c 0x0 0x0 0x0 0x80000000 0x290 0x660 0x0 0x0 0x0 0x80000000 0x294 0x664 0x0 0x0 0x0 0x80000000 0x298 0x668 0x0 0x0 0x0 0x80000000 0x29c 0x66c 0x0 0x0 0x0 0x80000000 0x2a0 0x670 0x0 0x0 0x0 0x80000000 0x2a4 0x674 0x0 0x0 0x0 0x80000000 0x260 0x630 0x0 0x0 0x0 0x80000000 0x258 0x628 0x0 0x0 0x0 0x80000000 0x25c 0x62c 0x0 0x0 0x0 0x80000000 0x264 0x634 0x0 0x0 0x0 0x80000000>;
						linux,phandle = <0x23>;
						phandle = <0x23>;
					};

					ipu1grp-3 {
						fsl,pins = <0x268 0x638 0x0 0x0 0x0 0x80000000 0x26c 0x63c 0x0 0x0 0x0 0x80000000 0x270 0x640 0x0 0x0 0x0 0x80000000 0x274 0x644 0x0 0x0 0x0 0x80000000 0x278 0x648 0x0 0x0 0x0 0x80000000 0x27c 0x64c 0x0 0x0 0x0 0x80000000 0x280 0x650 0x0 0x0 0x0 0x80000000 0x284 0x654 0x0 0x0 0x0 0x80000000 0x288 0x658 0x0 0x0 0x0 0x80000000 0x28c 0x65c 0x0 0x0 0x0 0x80000000 0x290 0x660 0x0 0x0 0x0 0x80000000 0x294 0x664 0x0 0x0 0x0 0x80000000 0x298 0x668 0x0 0x0 0x0 0x80000000 0x29c 0x66c 0x0 0x0 0x0 0x80000000 0x2a0 0x670 0x0 0x0 0x0 0x80000000 0x2a4 0x674 0x0 0x0 0x0 0x80000000 0x258 0x628 0x0 0x0 0x0 0x80000000 0x25c 0x62c 0x0 0x0 0x0 0x80000000 0x264 0x634 0x0 0x0 0x0 0x80000000>;
					};

					ipu1grp-4 {
						fsl,pins = <0x15c 0x470 0x0 0x0 0x0 0x10 0x160 0x474 0x0 0x0 0x0 0x10 0x164 0x478 0x0 0x0 0x0 0x10 0x168 0x47c 0x0 0x0 0x0 0x10 0x170 0x484 0x0 0x0 0x0 0x10 0x174 0x488 0x0 0x0 0x0 0x10 0x178 0x48c 0x0 0x0 0x0 0x10 0x17c 0x490 0x0 0x0 0x0 0x10 0x180 0x494 0x0 0x0 0x0 0x10 0x184 0x498 0x0 0x0 0x0 0x10 0x188 0x49c 0x0 0x0 0x0 0x10 0x18c 0x4a0 0x0 0x0 0x0 0x10 0x190 0x4a4 0x0 0x0 0x0 0x10 0x194 0x4a8 0x0 0x0 0x0 0x10 0x198 0x4ac 0x0 0x0 0x0 0x10 0x19c 0x4b0 0x0 0x0 0x0 0x10 0x1a0 0x4b4 0x0 0x0 0x0 0x10 0x1a4 0x4b8 0x0 0x0 0x0 0x10 0x1a8 0x4bc 0x0 0x0 0x0 0x10 0x1ac 0x4c0 0x0 0x0 0x0 0x10 0x1b0 0x4c4 0x0 0x0 0x0 0x10 0x1b4 0x4c8 0x0 0x0 0x0 0x10 0x1b8 0x4cc 0x0 0x0 0x0 0x10 0x1bc 0x4d0 0x0 0x0 0x0 0x10 0x1c0 0x4d4 0x0 0x0 0x0 0x10 0x1c4 0x4d8 0x0 0x0 0x0 0x10 0x1c8 0x4dc 0x0 0x0 0x0 0x10 0x1cc 0x4e0 0x0 0x0 0x0 0x10>;
						linux,phandle = <0x33>;
						phandle = <0x33>;
					};
				};

				mlb {

					mlbgrp-1 {
						fsl,pins = <0x22c 0x5fc 0x900 0x7 0x1 0x71 0x230 0x600 0x908 0x7 0x1 0x71 0x234 0x604 0x904 0x7 0x1 0x71>;
					};

					mlbgrp-2 {
						fsl,pins = <0x1ec 0x500 0x900 0x0 0x0 0x80000000 0x230 0x600 0x908 0x7 0x1 0x80000000 0x234 0x604 0x904 0x7 0x1 0x80000000>;
					};
				};

				pwm1 {

					pwm1grp-1 {
						fsl,pins = <0x344 0x72c 0x0 0x3 0x0 0x1b0b1>;
						linux,phandle = <0xb>;
						phandle = <0xb>;
					};

					pwm1grp-2 {
						fsl,pins = <0x190 0x4a4 0x0 0x2 0x0 0x1b0b1>;
					};

					pwm1grp-3 {
						fsl,pins = <0x228 0x5f8 0x0 0x4 0x0 0x1b0b1>;
					};
				};

				pwm2 {

					pwm2grp-1 {
						fsl,pins = <0x194 0x4a8 0x0 0x2 0x0 0x1b0b1>;
					};

					pwm2grp-2 {
						fsl,pins = <0x224 0x5f4 0x0 0x4 0x0 0x1b0b1>;
					};

					pwm2grp-3 {
						fsl,pins = <0x34c 0x734 0x0 0x3 0x0 0x1b0b1>;
					};
				};

				pwm3 {

					pwm3grp-1 {
						fsl,pins = <0x320 0x708 0x0 0x2 0x0 0x1b0b1>;
					};

					pwm3grp-2 {
						fsl,pins = <0x33c 0x724 0x0 0x2 0x0 0x1b0b1>;
						linux,phandle = <0xc>;
						phandle = <0xc>;
					};
				};

				pwm4 {

					pwm4grp-1 {
						fsl,pins = <0x324 0x70c 0x0 0x2 0x0 0x1b0b1>;
					};

					pwm4grp-2 {
						fsl,pins = <0x348 0x730 0x0 0x2 0x0 0x1b0b1>;
						linux,phandle = <0xd>;
						phandle = <0xd>;
					};
				};

				spdif {

					spdifgrp-1 {
						fsl,pins = <0x210 0x5e0 0x914 0x6 0x2 0x1b0b0>;
					};

					spdifgrp-2 {
						fsl,pins = <0x248 0x618 0x914 0x4 0x3 0x1b0b0 0x24c 0x61c 0x0 0x4 0x0 0x1b0b0>;
					};
				};

				uart1 {

					uart1grp-1 {
						fsl,pins = <0x280 0x650 0x0 0x3 0x0 0x1b0b1 0x284 0x654 0x920 0x3 0x1 0x1b0b1>;
					};

					uart1grp-2 {
						fsl,pins = <0x2a8 0x690 0x0 0x1 0x0 0x1b0b1 0x2ac 0x694 0x920 0x1 0x3 0x1b0b1>;
						linux,phandle = <0x7>;
						phandle = <0x7>;
					};
				};

				uart2 {

					uart2grp-1 {
						fsl,pins = <0xbc 0x3d0 0x0 0x4 0x0 0x1b0b1 0xc0 0x3d4 0x928 0x4 0x1 0x1b0b1>;
						linux,phandle = <0x2d>;
						phandle = <0x2d>;
					};

					uart2grp-2 {
						fsl,pins = <0xbc 0x3d0 0x928 0x4 0x0 0x1b0b1 0xc0 0x3d4 0x0 0x4 0x0 0x1b0b1 0xc4 0x3d8 0x924 0x4 0x0 0x1b0b1 0xc8 0x3dc 0x0 0x4 0x0 0x1b0b1>;
					};
				};

				uart3 {

					uart3grp-1 {
						fsl,pins = <0x2f8 0x6e0 0x930 0x2 0x3 0x1b0b1 0x2f4 0x6dc 0x0 0x2 0x0 0x1b0b1 0xcc 0x3e0 0x0 0x4 0x0 0x1b0b1 0xb0 0x3c4 0x92c 0x2 0x1 0x1b0b1>;
					};

					uart3grp-2 {
						fsl,pins = <0xb8 0x3cc 0x930 0x2 0x1 0x1b0b1 0xb4 0x3c8 0x0 0x2 0x0 0x1b0b1 0xac 0x3c0 0x0 0x2 0x0 0x1b0b1 0xd0 0x3e4 0x92c 0x4 0x3 0x1b0b1>;
					};
				};

				uart4 {

					uart4grp-1 {
						fsl,pins = <0x1f8 0x5c8 0x0 0x4 0x0 0x1b0b1 0x1fc 0x5cc 0x938 0x4 0x1 0x1b0b1>;
					};
				};

				usbotg {

					usbotggrp-1 {
						fsl,pins = <0x224 0x5f4 0x4 0x3 0xff0d0101 0x17059>;
						linux,phandle = <0x15>;
						phandle = <0x15>;
					};

					usbotggrp-2 {
						fsl,pins = <0x1d8 0x4ec 0x4 0x0 0xff0d0100 0x17059>;
					};
				};

				usbh2 {

					usbh2grp-1 {
						fsl,pins = <0x58 0x36c 0x0 0x0 0x0 0x40013030 0x74 0x388 0x0 0x0 0x0 0x40013030>;
					};

					usbh2grp-2 {
						fsl,pins = <0x74 0x388 0x0 0x0 0x0 0x40017030>;
					};
				};

				usbh3 {

					usbh3grp-1 {
						fsl,pins = <0x6c 0x380 0x0 0x0 0x0 0x40013030 0x84 0x398 0x0 0x0 0x0 0x40013030>;
					};

					usbh3grp-2 {
						fsl,pins = <0x84 0x398 0x0 0x0 0x0 0x40017030>;
					};
				};

				usdhc1 {

					usdhc1grp-1 {
						fsl,pins = <0x348 0x730 0x0 0x0 0x0 0x17071 0x350 0x738 0x0 0x0 0x0 0x10071 0x340 0x728 0x0 0x0 0x0 0x17071 0x33c 0x724 0x0 0x0 0x0 0x17071 0x34c 0x734 0x0 0x0 0x0 0x17071 0x344 0x72c 0x0 0x0 0x0 0x17071>;
					};
				};

				usdhc2 {

					usdhc2grp-1 {
						fsl,pins = <0x358 0x740 0x0 0x0 0x0 0x17059 0x354 0x73c 0x0 0x0 0x0 0x10059 0x54 0x368 0x0 0x0 0x0 0x17059 0x4c 0x360 0x0 0x0 0x0 0x17059 0x50 0x364 0x0 0x0 0x0 0x17059 0x35c 0x744 0x0 0x0 0x0 0x17059 0x30c 0x6f4 0x0 0x1 0x0 0x17059 0x310 0x6f8 0x0 0x1 0x0 0x17059 0x314 0x6fc 0x0 0x1 0x0 0x17059 0x318 0x700 0x0 0x1 0x0 0x17059>;
					};

					usdhc2grp-2 {
						fsl,pins = <0x358 0x740 0x0 0x0 0x0 0x17059 0x354 0x73c 0x0 0x0 0x0 0x10059 0x54 0x368 0x0 0x0 0x0 0x17059 0x4c 0x360 0x0 0x0 0x0 0x17059 0x50 0x364 0x0 0x0 0x0 0x17059 0x35c 0x744 0x0 0x0 0x0 0x17059>;
					};
				};

				usdhc3 {

					usdhc3grp-1 {
						fsl,pins = <0x2b8 0x6a0 0x0 0x0 0x0 0x17059 0x2bc 0x6a4 0x0 0x0 0x0 0x10059 0x2c0 0x6a8 0x0 0x0 0x0 0x17059 0x2c4 0x6ac 0x0 0x0 0x0 0x17059 0x2c8 0x6b0 0x0 0x0 0x0 0x17059 0x2cc 0x6b4 0x0 0x0 0x0 0x17059 0x2b4 0x69c 0x0 0x0 0x0 0x17059 0x2b0 0x698 0x0 0x0 0x0 0x17059 0x2ac 0x694 0x0 0x0 0x0 0x17059 0x2a8 0x690 0x0 0x0 0x0 0x17059>;
					};

					usdhc3grp-1-100mhz {
						fsl,pins = <0x2b8 0x6a0 0x0 0x0 0x0 0x170b9 0x2bc 0x6a4 0x0 0x0 0x0 0x100b9 0x2c0 0x6a8 0x0 0x0 0x0 0x170b9 0x2c4 0x6ac 0x0 0x0 0x0 0x170b9 0x2c8 0x6b0 0x0 0x0 0x0 0x170b9 0x2cc 0x6b4 0x0 0x0 0x0 0x170b9 0x2b4 0x69c 0x0 0x0 0x0 0x170b9 0x2b0 0x698 0x0 0x0 0x0 0x170b9 0x2ac 0x694 0x0 0x0 0x0 0x170b9 0x2a8 0x690 0x0 0x0 0x0 0x170b9>;
					};

					usdhc3grp-1-200mhz {
						fsl,pins = <0x2b8 0x6a0 0x0 0x0 0x0 0x170f9 0x2bc 0x6a4 0x0 0x0 0x0 0x100f9 0x2c0 0x6a8 0x0 0x0 0x0 0x170f9 0x2c4 0x6ac 0x0 0x0 0x0 0x170f9 0x2c8 0x6b0 0x0 0x0 0x0 0x170f9 0x2cc 0x6b4 0x0 0x0 0x0 0x170f9 0x2b4 0x69c 0x0 0x0 0x0 0x170f9 0x2b0 0x698 0x0 0x0 0x0 0x170f9 0x2ac 0x694 0x0 0x0 0x0 0x170f9 0x2a8 0x690 0x0 0x0 0x0 0x170f9>;
					};

					usdhc3grp-2 {
						fsl,pins = <0x2b8 0x6a0 0x0 0x0 0x0 0x17059 0x2bc 0x6a4 0x0 0x0 0x0 0x10059 0x2c0 0x6a8 0x0 0x0 0x0 0x17059 0x2c4 0x6ac 0x0 0x0 0x0 0x17059 0x2c8 0x6b0 0x0 0x0 0x0 0x17059 0x2cc 0x6b4 0x0 0x0 0x0 0x17059>;
						linux,phandle = <0x1b>;
						phandle = <0x1b>;
					};
				};

				usdhc4 {

					usdhc4grp-1 {
						fsl,pins = <0x2f4 0x6dc 0x0 0x0 0x0 0x17059 0x2f8 0x6e0 0x0 0x0 0x0 0x10059 0x31c 0x704 0x0 0x1 0x0 0x17059 0x320 0x708 0x0 0x1 0x0 0x17059 0x324 0x70c 0x0 0x1 0x0 0x17059 0x328 0x710 0x0 0x1 0x0 0x17059 0x32c 0x714 0x0 0x1 0x0 0x17059 0x330 0x718 0x0 0x1 0x0 0x17059 0x334 0x71c 0x0 0x1 0x0 0x17059 0x338 0x720 0x0 0x1 0x0 0x17059>;
					};

					usdhc4grp-2 {
						fsl,pins = <0x2f4 0x6dc 0x0 0x0 0x0 0x17059 0x2f8 0x6e0 0x0 0x0 0x0 0x10059 0x31c 0x704 0x0 0x1 0x0 0x17059 0x320 0x708 0x0 0x1 0x0 0x17059 0x324 0x70c 0x0 0x1 0x0 0x17059 0x328 0x710 0x0 0x1 0x0 0x17059>;
						linux,phandle = <0x1e>;
						phandle = <0x1e>;
					};
				};

				weim {

					weim_cs0grp-1 {
						fsl,pins = <0xf8 0x40c 0x0 0x0 0x0 0xb0b1>;
					};

					weim_norgrp-1 {
						fsl,pins = <0x100 0x414 0x0 0x0 0x0 0xb0b1 0x104 0x418 0x0 0x0 0x0 0xb0b1 0x154 0x468 0x0 0x0 0x0 0xb060 0x90 0x3a4 0x0 0x0 0x0 0x1b0b0 0x94 0x3a8 0x0 0x0 0x0 0x1b0b0 0x98 0x3ac 0x0 0x0 0x0 0x1b0b0 0x9c 0x3b0 0x0 0x0 0x0 0x1b0b0 0xa0 0x3b4 0x0 0x0 0x0 0x1b0b0 0xa4 0x3b8 0x0 0x0 0x0 0x1b0b0 0xa8 0x3bc 0x0 0x0 0x0 0x1b0b0 0xac 0x3c0 0x0 0x0 0x0 0x1b0b0 0xb4 0x3c8 0x0 0x0 0x0 0x1b0b0 0xb8 0x3cc 0x0 0x0 0x0 0x1b0b0 0xbc 0x3d0 0x0 0x0 0x0 0x1b0b0 0xc0 0x3d4 0x0 0x0 0x0 0x1b0b0 0xc4 0x3d8 0x0 0x0 0x0 0x1b0b0 0xc8 0x3dc 0x0 0x0 0x0 0x1b0b0 0xcc 0x3e0 0x0 0x0 0x0 0x1b0b0 0xd0 0x3e4 0x0 0x0 0x0 0x1b0b0 0xd8 0x3ec 0x0 0x0 0x0 0xb0b1 0xdc 0x3f0 0x0 0x0 0x0 0xb0b1 0xe0 0x3f4 0x0 0x0 0x0 0xb0b1 0xe4 0x3f8 0x0 0x0 0x0 0xb0b1 0xe8 0x3fc 0x0 0x0 0x0 0xb0b1 0xec 0x400 0x0 0x0 0x0 0xb0b1 0xf0 0x404 0x0 0x0 0x0 0xb0b1 0xf4 0x408 0x0 0x0 0x0 0xb0b1 0x150 0x464 0x0 0x0 0x0 0xb0b1 0x14c 0x460 0x0 0x0 0x0 0xb0b1 0x148 0x45c 0x0 0x0 0x0 0xb0b1 0x144 0x458 0x0 0x0 0x0 0xb0b1 0x140 0x454 0x0 0x0 0x0 0xb0b1 0x13c 0x450 0x0 0x0 0x0 0xb0b1 0x138 0x44c 0x0 0x0 0x0 0xb0b1 0x134 0x448 0x0 0x0 0x0 0xb0b1 0x130 0x444 0x0 0x0 0x0 0xb0b1 0x12c 0x440 0x0 0x0 0x0 0xb0b1 0x128 0x43c 0x0 0x0 0x0 0xb0b1 0x124 0x438 0x0 0x0 0x0 0xb0b1 0x120 0x434 0x0 0x0 0x0 0xb0b1 0x11c 0x430 0x0 0x0 0x0 0xb0b1 0x118 0x42c 0x0 0x0 0x0 0xb0b1 0x114 0x428 0x0 0x0 0x0 0xb0b1>;
					};
				};

				ipu2 {

					ipu2grp-1 {
						fsl,pins = <0x15c 0x470 0x0 0x1 0x0 0x10 0x160 0x474 0x0 0x1 0x0 0x10 0x164 0x478 0x0 0x1 0x0 0x10 0x168 0x47c 0x0 0x1 0x0 0x10 0x16c 0x480 0x0 0x1 0x0 0x80000000 0x170 0x484 0x0 0x1 0x0 0x10 0x174 0x488 0x0 0x1 0x0 0x10 0x178 0x48c 0x0 0x1 0x0 0x10 0x17c 0x490 0x0 0x1 0x0 0x10 0x180 0x494 0x0 0x1 0x0 0x10 0x184 0x498 0x0 0x1 0x0 0x10 0x188 0x49c 0x0 0x1 0x0 0x10 0x18c 0x4a0 0x0 0x1 0x0 0x10 0x190 0x4a4 0x0 0x1 0x0 0x10 0x194 0x4a8 0x0 0x1 0x0 0x10 0x198 0x4ac 0x0 0x1 0x0 0x10 0x19c 0x4b0 0x0 0x1 0x0 0x10 0x1a0 0x4b4 0x0 0x1 0x0 0x10 0x1a4 0x4b8 0x0 0x1 0x0 0x10 0x1a8 0x4bc 0x0 0x1 0x0 0x10 0x1ac 0x4c0 0x0 0x1 0x0 0x10 0x1b0 0x4c4 0x0 0x1 0x0 0x10 0x1b4 0x4c8 0x0 0x1 0x0 0x10 0x1b8 0x4cc 0x0 0x1 0x0 0x10 0x1bc 0x4d0 0x0 0x1 0x0 0x10 0x1c0 0x4d4 0x0 0x1 0x0 0x10 0x1c4 0x4d8 0x0 0x1 0x0 0x10 0x1c8 0x4dc 0x0 0x1 0x0 0x10 0x1cc 0x4e0 0x0 0x1 0x0 0x10>;
					};
				};

				imx6q-sabrelite {

					hoggrp-1 {
						fsl,pins = <0x308 0x6f0 0x0 0x5 0x0 0x1b0b0 0x300 0x6e8 0x0 0x5 0x0 0x1b0b0 0x30c 0x6f4 0x0 0x5 0x0 0x1b0b0 0x304 0x6ec 0x0 0x5 0x0 0x1b0b0 0x250 0x620 0x0 0x5 0x0 0x1b0b0 0x254 0x624 0x0 0x5 0x0 0x1b0b0 0x9c 0x3b0 0x0 0x5 0x0 0x80000000 0xa8 0x3bc 0x0 0x5 0x0 0x80000000 0xac 0x3c0 0x0 0x5 0x0 0x80000000 0x1e8 0x4fc 0x0 0x5 0x0 0x1b0b0 0x2b0 0x698 0x0 0x5 0x0 0x80000000 0x2b4 0x69c 0x0 0x5 0x0 0x1f0b0 0x314 0x6fc 0x0 0x5 0x0 0x80000000 0x318 0x700 0x0 0x5 0x0 0x80000000 0x220 0x5f0 0x0 0x0 0x0 0xb0 0x234 0x604 0x0 0x5 0x0 0x80000000 0x238 0x608 0x0 0x5 0x0 0x80000000 0x228 0x5f8 0x0 0x5 0x0 0x80000000 0x16c 0x480 0x0 0x5 0x0 0x1b0b0 0x2dc 0x6c4 0x0 0x5 0x0 0xb0b0 0x310 0x6f8 0x0 0x5 0x0 0xb0 0x22c 0x5fc 0x0 0x4 0x0 0xb0 0x230 0x600 0x0 0x5 0x0 0xb0 0x244 0x614 0x0 0x5 0x0 0xb0 0x24c 0x61c 0x0 0x5 0x0 0xb0b0>;
						linux,phandle = <0x11>;
						phandle = <0x11>;
					};

					pinctrl_ov5640 {
						fsl,pins = <0xf0 0x404 0x8b8 0x2 0x1 0xb0b1 0xec 0x400 0x8bc 0x2 0x1 0xb0b1 0xe8 0x3fc 0x8c0 0x2 0x1 0xb0b1 0xe4 0x3f8 0x8c4 0x2 0x1 0xb0b1 0xe0 0x3f4 0x8c8 0x2 0x1 0xb0b1 0xdc 0x3f0 0x8cc 0x2 0x1 0xb0b1 0xd8 0x3ec 0x8d0 0x2 0x1 0xb0b1 0x8c 0x3a0 0x8d4 0x3 0x0 0xb0b1 0x13c 0x450 0x8d8 0x2 0x1 0xb0b1 0xf4 0x408 0x8e0 0x2 0x1 0xb0b1 0x140 0x454 0x8dc 0x2 0x1 0xb0b1 0x144 0x458 0x8e4 0x2 0x1 0xb0b1>;
						linux,phandle = <0x28>;
						phandle = <0x28>;
					};

					pinctrl_ov5640_gpios {
						fsl,pins = <0x148 0x45c 0x0 0x5 0x0 0xb0b0 0x14c 0x460 0x0 0x5 0x0 0x30b0>;
						linux,phandle = <0x29>;
						phandle = <0x29>;
					};
				};
			};

			ldb@020e0008 {
				compatible = "fsl,imx6q-ldb", "fsl,imx53-ldb";
				reg = <0x20e0000 0x4000>;
				clocks = <0x2 0x87 0x2 0x88 0x2 0x27 0x2 0x28 0x2 0x29 0x2 0x2a 0x2 0xb8 0x2 0xb9 0x2 0xcd 0x2 0xce 0x2 0xcf 0x2 0xd0>;
				clock-names = "ldb_di0", "ldb_di1", "ipu1_di0_sel", "ipu1_di1_sel", "ipu2_di0_sel", "ipu2_di1_sel", "di0_div_3_5", "di1_div_3_5", "di0_div_7", "di1_div_7", "di0_div_sel", "di1_div_sel";
				status = "okay";
				ipu_id = <0x0>;
				disp_id = <0x1>;
				ext_ref = <0x1>;
				mode = "sin0";
				sec_ipu_id = <0x1>;
				sec_disp_id = <0x1>;
			};

			dcic@020e4000 {
				reg = <0x20e4000 0x4000>;
				interrupts = <0x0 0x7c 0x4>;
			};

			dcic@020e8000 {
				reg = <0x20e8000 0x4000>;
				interrupts = <0x0 0x7d 0x4>;
			};

			sdma@020ec000 {
				compatible = "fsl,imx6q-sdma", "fsl,imx35-sdma";
				reg = <0x20ec000 0x4000>;
				interrupts = <0x0 0x2 0x4>;
				clocks = <0x2 0x9b 0x2 0x9b>;
				clock-names = "ipg", "ahb";
				#dma-cells = <0x3>;
				fsl,sdma-ram-script-name = "imx/sdma/sdma-imx6q.bin";
				linux,phandle = <0x4>;
				phandle = <0x4>;
			};
		};

		aips-bus@02100000 {
			compatible = "fsl,aips-bus", "simple-bus";
			#address-cells = <0x1>;
			#size-cells = <0x1>;
			reg = <0x2100000 0x100000>;
			ranges;

			caam@2100000 {
				compatible = "fsl,sec-v4.0";
				#address-cells = <0x1>;
				#size-cells = <0x1>;
				reg = <0x2100000 0x40000>;
				ranges = <0x0 0x2100000 0x40000>;
				interrupt-parent = <0x1>;
				clocks = <0x2 0xd5 0x2 0xd6 0x2 0xd7 0x2 0xc4>;
				clock-names = "caam_mem", "caam_aclk", "caam_ipg", "caam_emi_slow";

				jr0@1000 {
					compatible = "fsl,sec-v4.0-job-ring";
					reg = <0x1000 0x1000>;
					interrupt-parent = <0x1>;
					interrupts = <0x0 0x69 0x4>;
				};

				jr1@2000 {
					compatible = "fsl,sec-v4.0-job-ring";
					reg = <0x2000 0x1000>;
					interrupt-parent = <0x1>;
					interrupts = <0x0 0x6a 0x4>;
				};
			};

			aipstz@0217c000 {
				reg = <0x217c000 0x4000>;
			};

			usb@02184000 {
				compatible = "fsl,imx6q-usb", "fsl,imx27-usb";
				reg = <0x2184000 0x200>;
				interrupts = <0x0 0x2b 0x4>;
				clocks = <0x2 0xa2>;
				fsl,usbphy = <0x12>;
				fsl,usbmisc = <0x13 0x0>;
				fsl,anatop = <0xf>;
				status = "okay";
				vbus-supply = <0x14>;
				pinctrl-names = "default";
				pinctrl-0 = <0x15>;
				disable-over-current;
			};

			usb@02184200 {
				compatible = "fsl,imx6q-usb", "fsl,imx27-usb";
				reg = <0x2184200 0x200>;
				interrupts = <0x0 0x28 0x4>;
				clocks = <0x2 0xa2>;
				fsl,usbphy = <0x16>;
				fsl,usbmisc = <0x13 0x1>;
				status = "okay";
			};

			usb@02184400 {
				compatible = "fsl,imx6q-usb", "fsl,imx27-usb";
				reg = <0x2184400 0x200>;
				interrupts = <0x0 0x29 0x4>;
				clocks = <0x2 0xa2>;
				fsl,usbmisc = <0x13 0x2>;
				phy_type = "hsic";
				fsl,usbphy = <0x17>;
				fsl,anatop = <0xf>;
				status = "disabled";
			};

			usb@02184600 {
				compatible = "fsl,imx6q-usb", "fsl,imx27-usb";
				reg = <0x2184600 0x200>;
				interrupts = <0x0 0x2a 0x4>;
				clocks = <0x2 0xa2>;
				fsl,usbmisc = <0x13 0x3>;
				phy_type = "hsic";
				fsl,usbphy = <0x18>;
				fsl,anatop = <0xf>;
				status = "disabled";
			};

			usbmisc@02184800 {
				#index-cells = <0x1>;
				compatible = "fsl,imx6q-usbmisc";
				reg = <0x2184800 0x200>;
				clocks = <0x2 0xa2>;
				linux,phandle = <0x13>;
				phandle = <0x13>;
			};

			ethernet@02188000 {
				compatible = "fsl,imx6q-fec";
				reg = <0x2188000 0x4000>;
				interrupts = <0x0 0x76 0x4 0x0 0x77 0x4>;
				clocks = <0x2 0x75 0x2 0x75 0x2 0xbe>;
				clock-names = "ipg", "ahb", "ptp";
				status = "okay";
				pinctrl-names = "default";
				pinctrl-0 = <0x19>;
				phy-mode = "mii";
				#address-cells = <0x0>;
				#size-cells = <0x1>;

				phy_int {
					reg = <0x6>;
					interrupt-parent = <0x1a>;
					interrupts = <0x1c 0x8>;
				};
			};

			mlb@0218c000 {
				compatible = "fsl,imx6q-mlb150";
				reg = <0x218c000 0x4000>;
				interrupts = <0x0 0x35 0x4 0x0 0x75 0x4 0x0 0x7e 0x4>;
				clocks = <0x2 0x8b 0x2 0xaf>;
				clock-names = "mlb", "pll8_mlb";
				iram = <0x8>;
				status = "disabled";
			};

			usdhc@02190000 {
				compatible = "fsl,imx6q-usdhc";
				reg = <0x2190000 0x4000>;
				interrupts = <0x0 0x16 0x4>;
				clocks = <0x2 0xa3 0x2 0xa3 0x2 0xa3>;
				clock-names = "ipg", "ahb", "per";
				bus-width = <0x4>;
				status = "disabled";
			};

			usdhc@02194000 {
				compatible = "fsl,imx6q-usdhc";
				reg = <0x2194000 0x4000>;
				interrupts = <0x0 0x17 0x4>;
				clocks = <0x2 0xa4 0x2 0xa4 0x2 0xa4>;
				clock-names = "ipg", "ahb", "per";
				bus-width = <0x4>;
				status = "disabled";
			};

			usdhc@02198000 {
				compatible = "fsl,imx6q-usdhc";
				reg = <0x2198000 0x4000>;
				interrupts = <0x0 0x18 0x4>;
				clocks = <0x2 0xa5 0x2 0xa5 0x2 0xa5>;
				clock-names = "ipg", "ahb", "per";
				bus-width = <0x4>;
				status = "okay";
				pinctrl-names = "default";
				pinctrl-0 = <0x1b>;
				cd-gpios = <0x1c 0x0 0x0>;
				wp-gpios = <0x1c 0x1 0x0>;
				vmmc-supply = <0x1d>;
			};

			usdhc@0219c000 {
				compatible = "fsl,imx6q-usdhc";
				reg = <0x219c000 0x4000>;
				interrupts = <0x0 0x19 0x4>;
				clocks = <0x2 0xa6 0x2 0xa6 0x2 0xa6>;
				clock-names = "ipg", "ahb", "per";
				bus-width = <0x4>;
				status = "okay";
				pinctrl-names = "default";
				pinctrl-0 = <0x1e>;
				cd-gpios = <0x1f 0x6 0x0>;
				vmmc-supply = <0x1d>;
			};

			i2c@021a0000 {
				#address-cells = <0x1>;
				#size-cells = <0x0>;
				compatible = "fsl,imx6q-i2c", "fsl,imx21-i2c";
				reg = <0x21a0000 0x4000>;
				interrupts = <0x0 0x24 0x4>;
				clocks = <0x2 0x7d>;
				status = "okay";
				clock-frequency = <0x186a0>;
				pinctrl-names = "default";
				pinctrl-0 = <0x20>;
/*
				sgtl5000@0a {
					compatible = "fsl,sgtl5000";
					reg = <0xa>;
					clocks = <0x2 0xc9>;
					VDDA-supply = <0x21>;
					VDDIO-supply = <0x1d>;
					linux,phandle = <0x32>;
					phandle = <0x32>;
				};
*/
			};

			i2c@021a4000 {
				#address-cells = <0x1>;
				#size-cells = <0x0>;
				compatible = "fsl,imx6q-i2c", "fsl,imx21-i2c";
				reg = <0x21a4000 0x4000>;
				interrupts = <0x0 0x25 0x4>;
				clocks = <0x2 0x7e>;
				status = "okay";
				clock-frequency = <0x186a0>;
				pinctrl-names = "default";
				pinctrl-0 = <0x22>;

				edid@50 {
					compatible = "fsl,imx6-hdmi-i2c";
					reg = <0x50>;
				};

				ov5642@3d {
					compatible = "ovti,ov5642";
					reg = <0x3d>;
					pinctrl-names = "default";
					pinctrl-0 = <0x23>;
					clocks = <0x2 0xc8>;
					clock-names = "csi_mclk";
					DOVDD-supply = <0x24>;
					AVDD-supply = <0x21>;
					DVDD-supply = <0x24>;
					pwn-gpios = <0x1a 0x6 0x1>;
					rst-gpios = <0x1a 0x8 0x0>;
					ipu_id = <0x0>;
					csi_id = <0x0>;
					mclk = <0x16e3600>;
					mclk_source = <0x0>;
				};

				ov5640_mipi@3e {
					compatible = "ovti,ov5640_mipi";
					reg = <0x3e>;
					clocks = <0x2 0x93>;
					clock-names = "csi_mclk";
					DOVDD-supply = <0x24>;
					AVDD-supply = <0x21>;
					DVDD-supply = <0x24>;
					pwn-gpios = <0x25 0x9 0x1>;
					rst-gpios = <0x1f 0x5 0x0>;
					ipu_id = <0x0>;
					csi_id = <0x1>;
					mclk = <0x14fb180>;
					mclk_source = <0x0>;
					pwms = <0x26 0x0 0x2d>;
				};
			};

			i2c@021a8000 {
				#address-cells = <0x1>;
				#size-cells = <0x0>;
				compatible = "fsl,imx6q-i2c", "fsl,imx21-i2c";
				reg = <0x21a8000 0x4000>;
				interrupts = <0x0 0x26 0x4>;
				clocks = <0x2 0x7f>;
				status = "okay";
				clock-frequency = <0x186a0>;
				pinctrl-names = "default";
				pinctrl-0 = <0x27>;

				egalax_ts@04 {
					compatible = "eeti,egalax_ts";
					reg = <0x4>;
					interrupt-parent = <0x1a>;
					interrupts = <0x9 0x2>;
					wakeup-gpios = <0x1a 0x9 0x0>;
				};

				ft5x06_ts@38 {
					compatible = "ft5x06-ts,ft5x06-ts";
					reg = <0x38>;
					interrupt-parent = <0x1a>;
					interrupts = <0x9 0x2>;
					wakeup-gpios = <0x1a 0x9 0x0>;
				};

				ov5640@3c {
					compatible = "ovti,ov5640";
					reg = <0x3c>;
					pinctrl-names = "default";
					pinctrl-0 = <0x28 0x29>;
					clocks = <0x2a 0x0>;
					clock-names = "csi_mclk";
					DOVDD-supply = <0x24>;
					AVDD-supply = <0x21>;
					DVDD-supply = <0x24>;
					pwn-gpios = <0x5 0xd 0x1>;
					rst-gpios = <0x5 0xe 0x0>;
					csi_id = <0x1>;
					mclk = <0x16e3600>;
					mclk_source = <0x0>;
					ipu_id = <0x1>;
				};

				tsc2004@48 {
					compatible = "tsc2004,tsc2004";
					reg = <0x48>;
					interrupt-parent = <0x2b>;
					interrupts = <0x14 0x2>;
					wakeup-gpios = <0x2b 0x14 0x0>;
				};
			};

			romcp@021ac000 {
				reg = <0x21ac000 0x4000>;
			};

			mmdc0-1@021b0000 {
				compatible = "fsl,imx6q-mmdc-combine";
				reg = <0x21b0000 0x8000>;
			};

			mmdc@021b0000 {
				compatible = "fsl,imx6q-mmdc";
				reg = <0x21b0000 0x4000>;
			};

			mmdc@021b4000 {
				reg = <0x21b4000 0x4000>;
			};

			weim@021b8000 {
				compatible = "fsl,imx6q-weim";
				reg = <0x21b8000 0x4000>;
				interrupts = <0x0 0xe 0x4>;
				clocks = <0x2 0xc4>;
			};

			ocotp-ctrl@021bc000 {
				compatible = "syscon";
				reg = <0x21bc000 0x4000>;
				linux,phandle = <0x10>;
				phandle = <0x10>;
			};

			ocotp-fuse@021bc000 {
				compatible = "fsl,imx6q-ocotp";
				reg = <0x21bc000 0x4000>;
				clocks = <0x2 0x80>;
			};

			tzasc@021d0000 {
				reg = <0x21d0000 0x4000>;
				interrupts = <0x0 0x6c 0x4>;
			};

			tzasc@021d4000 {
				reg = <0x21d4000 0x4000>;
				interrupts = <0x0 0x6d 0x4>;
			};

			audmux@021d8000 {
				compatible = "fsl,imx6q-audmux", "fsl,imx31-audmux";
				reg = <0x21d8000 0x4000>;
				status = "okay";
				pinctrl-names = "default";
				pinctrl-0 = <0x2c>;
			};

			mipi_csi@021dc000 {
				compatible = "fsl,imx6q-mipi-csi2";
				reg = <0x21dc000 0x4000>;
				interrupts = <0x0 0x64 0x4 0x0 0x65 0x4>;
				clocks = <0x2 0x8a 0x2 0x35 0x2 0xcc>;
				clock-names = "dphy_clk", "pixel_clk", "cfg_clk";
				status = "okay";
				ipu_id = <0x0>;
				csi_id = <0x1>;
				v_channel = <0x0>;
				lanes = <0x2>;
			};

			vdoa@021e4000 {
				compatible = "fsl,imx6q-vdoa";
				reg = <0x21e4000 0x4000>;
				interrupts = <0x0 0x12 0x4>;
				clocks = <0x2 0xca>;
				iram = <0x8>;
			};

			serial@021e8000 {
				compatible = "fsl,imx6q-uart", "fsl,imx21-uart";
				reg = <0x21e8000 0x4000>;
				interrupts = <0x0 0x1b 0x4>;
				clocks = <0x2 0xa0 0x2 0xa1>;
				clock-names = "ipg", "per";
				dmas = <0x4 0x1b 0x4 0x0 0x4 0x1c 0x4 0x0>;
				dma-names = "rx", "tx";
				status = "okay";
				pinctrl-names = "default";
				pinctrl-0 = <0x2d>;
			};

			serial@021ec000 {
				compatible = "fsl,imx6q-uart", "fsl,imx21-uart";
				reg = <0x21ec000 0x4000>;
				interrupts = <0x0 0x1c 0x4>;
				clocks = <0x2 0xa0 0x2 0xa1>;
				clock-names = "ipg", "per";
				dmas = <0x4 0x1d 0x4 0x0 0x4 0x1e 0x4 0x0>;
				dma-names = "rx", "tx";
				status = "disabled";
			};

			serial@021f0000 {
				compatible = "fsl,imx6q-uart", "fsl,imx21-uart";
				reg = <0x21f0000 0x4000>;
				interrupts = <0x0 0x1d 0x4>;
				clocks = <0x2 0xa0 0x2 0xa1>;
				clock-names = "ipg", "per";
				dmas = <0x4 0x1f 0x4 0x0 0x4 0x20 0x4 0x0>;
				dma-names = "rx", "tx";
				status = "disabled";
			};

			serial@021f4000 {
				compatible = "fsl,imx6q-uart", "fsl,imx21-uart";
				reg = <0x21f4000 0x4000>;
				interrupts = <0x0 0x1e 0x4>;
				clocks = <0x2 0xa0 0x2 0xa1>;
				clock-names = "ipg", "per";
				dmas = <0x4 0x21 0x4 0x0 0x4 0x22 0x4 0x0>;
				dma-names = "rx", "tx";
				status = "disabled";
			};

			mipi@021e0000 {
				compatible = "fsl,imx6q-mipi-dsi";
				reg = <0x21e0000 0x4000>;
				interrupts = <0x0 0x66 0x4>;
				gpr = <0xe>;
				clocks = <0x2 0x8a 0x2 0xcc>;
				clock-names = "mipi_pllref_clk", "mipi_cfg_clk";
				status = "disabled";
			};
		};


		ipu@02400000 {
			compatible = "fsl,imx6q-ipu";
			reg = <0x2400000 0x400000>;
			interrupts = <0x0 0x6 0x4 0x0 0x5 0x4>;
			clocks = <0x2 0x82 0x2 0x83 0x2 0x84 0x2 0x27 0x2 0x28 0x2 0x87 0x2 0x88>;
			clock-names = "bus", "di0", "di1", "di0_sel", "di1_sel", "ldb_di0", "ldb_di1";
			resets = <0x9 0x2>;
			bypass_reset = <0x0>;
		};


		busfreq {
			compatible = "fsl,imx6_busfreq";
			clocks = <0x2 0xab 0x2 0x6 0x2 0xb 0x2 0x68 0x2 0xac 0x2 0x3a 0x2 0x12 0x2 0x3c 0x2 0x14 0x2 0x3>;
			clock-names = "pll2_bus", "pll2_pfd2_396m", "pll2_198m", "arm", "pll3_usb_otg", "periph", "periph_pre", "periph_clk2", "periph_clk2_sel", "osc";
			interrupts = <0x0 0x6b 0x4 0x0 0x70 0x4 0x0 0x71 0x4 0x0 0x72 0x4>;
			interrupt-names = "irq_busfreq_0", "irq_busfreq_1", "irq_busfreq_2", "irq_busfreq_3";
			fsl,max_ddr_freq = <0x1f78a400>;
		};

		sram@00900000 {
			compatible = "mmio-sram";
			reg = <0x904000 0x3c000>;
			clocks = <0x2 0x8e>;
			linux,phandle = <0x8>;
			phandle = <0x8>;
		};

		sata@02200000 {
			compatible = "fsl,imx6q-ahci";
			reg = <0x2200000 0x4000>;
			interrupts = <0x0 0x27 0x4>;
			clocks = <0x2 0x9a 0x2 0xbb 0x2 0x69>;
			clock-names = "sata", "sata_ref", "ahb";
			status = "okay";
		};
	};

	cpus {
		#address-cells = <0x1>;
		#size-cells = <0x0>;

		cpu@0 {
			compatible = "arm,cortex-a9";
			device_type = "cpu";
			reg = <0x0>;
			next-level-cache = <0x2e>;
			operating-points = <0x124f80 0x137478 0xf32a0 0x1312d0 0xd0020 0x1312d0 0xc15c0 0x118c30 0x60ae0 0xee098>;
			fsl,soc-operating-points = <0x124f80 0x137478 0xf32a0 0x1312d0 0xd0020 0x1312d0 0xc15c0 0x11edd8 0x60ae0 0x11edd8>;
			clock-latency = <0xee6c>;
			clocks = <0x2 0x68 0x2 0x6 0x2 0x10 0x2 0x11 0x2 0xaa>;
			clock-names = "arm", "pll2_pfd2_396m", "step", "pll1_sw", "pll1_sys";
			arm-supply = <0x2f>;
			pu-supply = <0xa>;
			soc-supply = <0x30>;
		};

		cpu@1 {
			compatible = "arm,cortex-a9";
			device_type = "cpu";
			reg = <0x1>;
			next-level-cache = <0x2e>;
		};

		cpu@2 {
			compatible = "arm,cortex-a9";
			device_type = "cpu";
			reg = <0x2>;
			next-level-cache = <0x2e>;
		};

		cpu@3 {
			compatible = "arm,cortex-a9";
			device_type = "cpu";
			reg = <0x3>;
			next-level-cache = <0x2e>;
		};
	};

	regulators {
		compatible = "simple-bus";

		1p8v {
			compatible = "regulator-fixed";
			regulator-name = "1P8V";
			regulator-min-microvolt = <0x1b7740>;
			regulator-max-microvolt = <0x1b7740>;
			regulator-always-on;
			linux,phandle = <0x24>;
			phandle = <0x24>;
		};

		2p5v {
			compatible = "regulator-fixed";
			regulator-name = "2P5V";
			regulator-min-microvolt = <0x2625a0>;
			regulator-max-microvolt = <0x2625a0>;
			regulator-always-on;
			linux,phandle = <0x21>;
			phandle = <0x21>;
		};

		3p3v {
			compatible = "regulator-fixed";
			regulator-name = "3P3V";
			regulator-min-microvolt = <0x325aa0>;
			regulator-max-microvolt = <0x325aa0>;
			regulator-always-on;
			linux,phandle = <0x1d>;
			phandle = <0x1d>;
		};

		usb_otg_vbus {
			compatible = "regulator-fixed";
			regulator-name = "usb_otg_vbus";
			regulator-min-microvolt = <0x4c4b40>;
			regulator-max-microvolt = <0x4c4b40>;
			gpio = <0x5 0x16 0x0>;
			enable-active-high;
			linux,phandle = <0x14>;
			phandle = <0x14>;
		};
	};

	gpio-keys {
		compatible = "gpio-keys";

		power {
			label = "Power Button";
			gpios = <0x1f 0x3 0x0>;
			linux,code = <0x74>;
			gpio-key,wakeup;
		};

		menu {
			label = "Menu";
			gpios = <0x1f 0x1 0x0>;
			linux,code = <0x8b>;
		};

		home {
			label = "Home";
			gpios = <0x1f 0x4 0x0>;
			linux,code = <0x66>;
		};

		back {
			label = "Back";
			gpios = <0x1f 0x2 0x0>;
			linux,code = <0x9e>;
		};

		volume-up {
			label = "Volume Up";
			gpios = <0x1c 0xd 0x0>;
			linux,code = <0x73>;
		};

		volume-down {
			label = "Volume Down";
			gpios = <0x2b 0x5 0x0>;
			linux,code = <0x72>;
		};
	};

/*
	sound {
		compatible = "fsl,imx6q-sabrelite-sgtl5000", "fsl,imx-audio-sgtl5000";
		model = "imx6q-sabrelite-sgtl5000";
		ssi-controller = <0x31>;
		audio-codec = <0x32>;
		audio-routing = "MIC_IN", "Mic Jack", "Mic Jack", "Mic Bias", "Headphone Jack", "HP_OUT";
		mux-int-port = <0x1>;
		mux-ext-port = <0x4>;
	};
*/
/*
	fb@0 {
		compatible = "fsl,mxc_sdc_fb";
		disp_dev = "ldb";
		interface_pix_fmt = "RGB666";
		mode_str = "LDB-XGA";
		default_bpp = <0x10>;
		int_clk = <0x0>;
		late_init = <0x0>;
		status = "okay";
	};
	*/

	fb@1 {
		compatible = "fsl,mxc_sdc_fb";
		disp_dev = "hdmi";
		interface_pix_fmt = "RGB24";
		mode_str = "1920x1080M@60";
		default_bpp = <0x18>;
		int_clk = <0x0>;
		late_init = <0x0>;
		status = "okay";
	};
	
	/*

	fb@2 {
		compatible = "fsl,mxc_sdc_fb";
		disp_dev = "lcd";
		interface_pix_fmt = "RGB565";
		mode_str = "CLAA-WVGA";
		default_bpp = <0x10>;
		int_clk = <0x0>;
		late_init = <0x0>;
		status = "okay";
	};
	*/

	fb@3 {
		compatible = "fsl,mxc_sdc_fb";
		disp_dev = "ldb";
		interface_pix_fmt = "RGB666";
		mode_str = "LDB-XGA";
		default_bpp = <0x10>;
		int_clk = <0x0>;
		late_init = <0x0>;
		status = "okay";
	};


	lcd@0 {
		compatible = "fsl,lcd";
		ipu_id = <0x0>;
		disp_id = <0x0>;
		default_ifmt = "RGB565";
		pinctrl-names = "default";
		pinctrl-0 = <0x33>;
	};

	backlight_lcd {
		compatible = "pwm-backlight";
		pwms = <0x34 0x0 0x4c4b40>;
		brightness-levels = <0x0 0x4 0x8 0x10 0x20 0x40 0x80 0xff>;
		default-brightness-level = <0x7>;
	};

	backlight_lvds {
		compatible = "pwm-backlight";
		pwms = <0x35 0x0 0x4c4b40>;
		brightness-levels = <0x0 0x4 0x8 0x10 0x20 0x40 0x80 0xff>;
		default-brightness-level = <0x7>;
	};

	v4l2_cap_0 {
		compatible = "fsl,imx6q-v4l2-capture";
		ipu_id = <0x0>;
		csi_id = <0x0>;
		mclk_source = <0x0>;
		status = "okay";
	};

	v4l2_cap_1 {
		compatible = "fsl,imx6q-v4l2-capture";
		ipu_id = <0x0>;
		csi_id = <0x1>;
		mclk_source = <0x0>;
		status = "okay";
	};

	v4l2_cap_2 {
		compatible = "fsl,imx6q-v4l2-capture";
		ipu_id = <0x1>;
		csi_id = <0x1>;
		mclk_source = <0x0>;
		status = "okay";
	};

	v4l2_out {
		compatible = "fsl,mxc_v4l2_output";
		status = "okay";
	};
};
